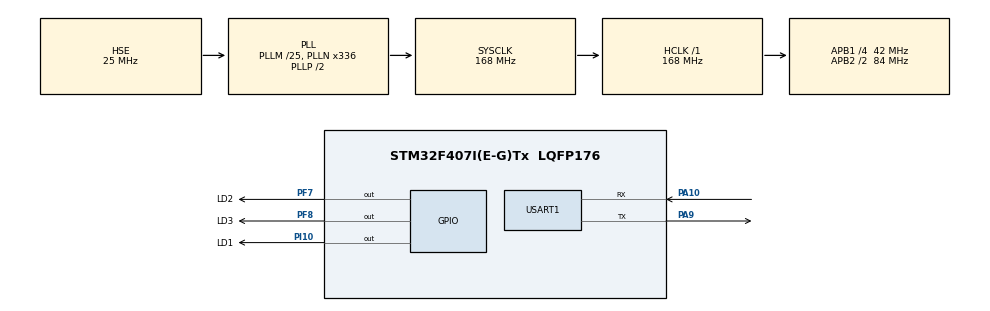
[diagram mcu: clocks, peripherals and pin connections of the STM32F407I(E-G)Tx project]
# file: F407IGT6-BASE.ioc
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Dma.Request0=USART1_RX
Dma.Request1=USART1_TX
Dma.USART1_RX.0.Direction=DMA_PERIPH_TO_MEMORY
Dma.USART1_RX.0.FIFOMode=DMA_FIFOMODE_DISABLE
Dma.USART1_RX.0.Instance=DMA2_Stream2
Dma.USART1_RX.0.MemDataAlignment=DMA_MDATAALIGN_BYTE
Dma.USART1_RX.0.MemInc=DMA_MINC_ENABLE
Dma.USART1_RX.0.Mode=DMA_CIRCULAR
Dma.USART1_RX.0.PeriphDataAlignment=DMA_PDATAALIGN_BYTE
Dma.USART1_RX.0.PeriphInc=DMA_PINC_DISABLE
Dma.USART1_RX.0.Priority=DMA_PRIORITY_MEDIUM
Dma.USART1_TX.1.Direction=DMA_MEMORY_TO_PERIPH
Dma.USART1_TX.1.FIFOMode=DMA_FIFOMODE_DISABLE
Dma.USART1_TX.1.Instance=DMA2_Stream7
Dma.USART1_TX.1.MemDataAlignment=DMA_MDATAALIGN_BYTE
Dma.USART1_TX.1.MemInc=DMA_MINC_ENABLE
Dma.USART1_TX.1.Mode=DMA_NORMAL
Dma.USART1_TX.1.PeriphDataAlignment=DMA_PDATAALIGN_BYTE
Dma.USART1_TX.1.PeriphInc=DMA_PINC_DISABLE
Dma.USART1_TX.1.Priority=DMA_PRIORITY_MEDIUM
Mcu.Family=STM32F4
Mcu.Name=STM32F407I(E-G)Tx
Mcu.Package=LQFP176
NVIC.DMA2_Stream2_IRQn=true\:0\:0\:false\:false\:true\:false\:true\:true
NVIC.DMA2_Stream7_IRQn=true\:0\:0\:false\:false\:true\:false\:true\:true
NVIC.PriorityGroup=NVIC_PRIORITYGROUP_4
NVIC.USART1_IRQn=true\:0\:0\:false\:false\:true\:true\:true\:true
PA10.GPIO_PuPd=GPIO_PULLUP
PA10.Mode=Asynchronous
PA10.Signal=USART1_RX
PA13.Mode=Serial_Wire
PA13.Signal=SYS_JTMS-SWDIO
PA14.Mode=Serial_Wire
PA14.Signal=SYS_JTCK-SWCLK
PA9.Mode=Asynchronous
PA9.Signal=USART1_TX
PF7.GPIO_Label=LD2
PF7.GPIO_Speed=GPIO_SPEED_FREQ_MEDIUM
PF7.Signal=GPIO_Output
PF8.GPIO_Label=LD3
PF8.GPIO_Speed=GPIO_SPEED_FREQ_MEDIUM
PF8.Signal=GPIO_Output
PH0-OSC_IN.Mode=HSE-External-Oscillator
PH0-OSC_IN.Signal=RCC_OSC_IN
PH1-OSC_OUT.Mode=HSE-External-Oscillator
PH1-OSC_OUT.Signal=RCC_OSC_OUT
PI10.GPIO_Label=LD1
PI10.GPIO_Speed=GPIO_SPEED_FREQ_MEDIUM
PI10.Signal=GPIO_Output
ProjectManager.HeapSize=0x200
ProjectManager.StackSize=0x1000
ProjectManager.TargetToolchain=MDK-ARM V5.32
RCC.48MHZClocksFreq_Value=84000000
RCC.AHBFreq_Value=168000000
RCC.APB1CLKDivider=RCC_HCLK_DIV4
RCC.APB1Freq_Value=42000000
RCC.APB1TimFreq_Value=84000000
RCC.APB2CLKDivider=RCC_HCLK_DIV2
RCC.APB2Freq_Value=84000000
RCC.APB2TimFreq_Value=168000000
RCC.CortexFreq_Value=168000000
RCC.HCLKFreq_Value=168000000
RCC.HSE_VALUE=25000000
RCC.HSI_VALUE=16000000
RCC.LSE_VALUE=32768
RCC.PLLM=25
RCC.PLLN=336
RCC.PLLSourceVirtual=RCC_PLLSOURCE_HSE
RCC.SYSCLKFreq_VALUE=168000000
RCC.SYSCLKSource=RCC_SYSCLKSOURCE_PLLCLK
RCC.VCOOutputFreq_Value=336000000
USART1.VirtualMode=VM_ASYNC
board=custom

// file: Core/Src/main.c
/* USER CODE BEGIN Header */
/**
  ******************************************************************************
  * @file           : main.c
  * @brief          : Main program body
  ******************************************************************************
  * @attention
  *
  * Copyright (c) 2024 STMicroelectronics.
  * All rights reserved.
  *
  * This software is licensed under terms that can be found in the LICENSE file
  * in the root directory of this software component.
  * If no LICENSE file comes with this software, it is provided AS-IS.
  *
  ******************************************************************************
  */
/* USER CODE END Header */
#include "main.h"
#include "dma.h"
#include "usart.h"
#include "gpio.h"

/* USER CODE BEGIN Includes */
uint32_t count = 0;
/* USER CODE END Includes */

void SystemClock_Config(void);

int main(void)
{

  /* MCU Configuration--------------------------------------------------------*/

  /* Reset of all peripherals, Initializes the Flash interface and the Systick. */
  HAL_Init();

  /* Configure the system clock */
  SystemClock_Config();

  /* Initialize all configured peripherals */
  MX_GPIO_Init();
  MX_DMA_Init();
  MX_USART1_UART_Init();

  /* Infinite loop */
  while (1)
  {

    /* USER CODE BEGIN 3 */
    HAL_GPIO_TogglePin(LD1_GPIO_Port,LD1_Pin);
    count++;
    HAL_Delay(50);
  }
  /* USER CODE END 3 */
}

void SystemClock_Config(void)
{
  RCC_OscInitTypeDef RCC_OscInitStruct = {0};
  RCC_ClkInitTypeDef RCC_ClkInitStruct = {0};

  /** Configure the main internal regulator output voltage
  */
  __HAL_RCC_PWR_CLK_ENABLE();
  __HAL_PWR_VOLTAGESCALING_CONFIG(PWR_REGULATOR_VOLTAGE_SCALE1);

  /** Initializes the RCC Oscillators according to the specified parameters
  * in the RCC_OscInitTypeDef structure.
  */
  RCC_OscInitStruct.OscillatorType = RCC_OSCILLATORTYPE_HSE;
  RCC_OscInitStruct.HSEState = RCC_HSE_ON;
  RCC_OscInitStruct.PLL.PLLState = RCC_PLL_ON;
  RCC_OscInitStruct.PLL.PLLSource = RCC_PLLSOURCE_HSE;
  RCC_OscInitStruct.PLL.PLLM = 25;
  RCC_OscInitStruct.PLL.PLLN = 336;
  RCC_OscInitStruct.PLL.PLLP = RCC_PLLP_DIV2;
  RCC_OscInitStruct.PLL.PLLQ = 4;
  if (HAL_RCC_OscConfig(&RCC_OscInitStruct) != HAL_OK)
  {
    Error_Handler();
  }

  /** Initializes the CPU, AHB and APB buses clocks
  */
  RCC_ClkInitStruct.ClockType = RCC_CLOCKTYPE_HCLK|RCC_CLOCKTYPE_SYSCLK
                              |RCC_CLOCKTYPE_PCLK1|RCC_CLOCKTYPE_PCLK2;
  RCC_ClkInitStruct.SYSCLKSource = RCC_SYSCLKSOURCE_PLLCLK;
  RCC_ClkInitStruct.AHBCLKDivider = RCC_SYSCLK_DIV1;
  RCC_ClkInitStruct.APB1CLKDivider = RCC_HCLK_DIV4;
  RCC_ClkInitStruct.APB2CLKDivider = RCC_HCLK_DIV2;

  if (HAL_RCC_ClockConfig(&RCC_ClkInitStruct, FLASH_LATENCY_5) != HAL_OK)
  {
    Error_Handler();
  }
}

void Error_Handler(void)
{
  __disable_irq();
  while (1)
  {
  }
}
